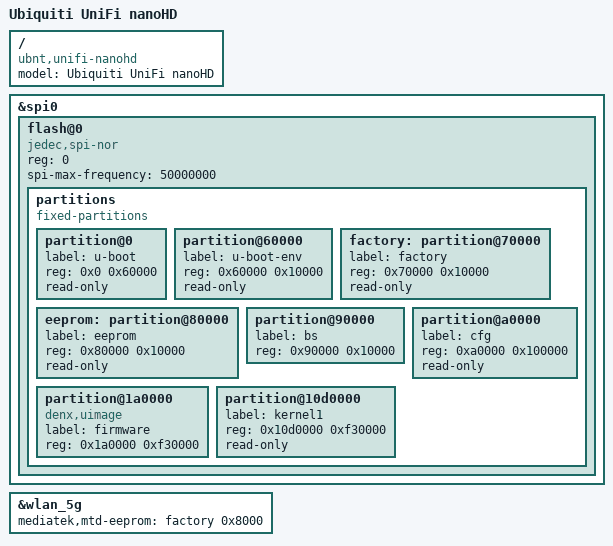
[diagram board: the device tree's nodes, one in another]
// SPDX-License-Identifier: GPL-2.0-or-later OR MIT

#include "mt7621_ubnt_unifi.dtsi"

/ {
	compatible = "ubnt,unifi-nanohd", "mediatek,mt7621-soc";
	model = "Ubiquiti UniFi nanoHD";
};

&spi0 {
	status = "okay";

	flash@0 {
		compatible = "jedec,spi-nor";
		reg = <0>;
		spi-max-frequency = <50000000>;

		partitions {
			compatible = "fixed-partitions";
			#address-cells = <1>;
			#size-cells = <1>;

			partition@0 {
				label = "u-boot";
				reg = <0x0 0x60000>;
				read-only;
			};

			partition@60000 {
				label = "u-boot-env";
				reg = <0x60000 0x10000>;
				read-only;
			};

			factory: partition@70000 {
				label = "factory";
				reg = <0x70000 0x10000>;
				read-only;
			};

			eeprom: partition@80000 {
				label = "eeprom";
				reg = <0x80000 0x10000>;
				read-only;
			};

			partition@90000 {
				label = "bs";
				reg = <0x90000 0x10000>;
			};

			partition@a0000 {
				label = "cfg";
				reg = <0xa0000 0x100000>;
				read-only;
			};

			partition@1a0000 {
				compatible = "denx,uimage";
				label = "firmware";
				reg = <0x1a0000 0xf30000>;
			};

			partition@10d0000 {
				label = "kernel1";
				reg = <0x10d0000 0xf30000>;
				read-only;
			};
		};
	};
};

&wlan_5g {
	mediatek,mtd-eeprom = <&factory 0x8000>;
};
